# CC1314R10 register map
File version: 1.0
CPU: CM33 1.0, other endian, MPU, FPU, 3 interrupt priority bits
Registers are 32-bit, read-write, reset 0x0 unless marked. A register's access mark holds for its fields unless they carry their own. Offsets are from the block's base; [hi:lo] are bit positions; {n}, {i} and the like mark numbered series.

## WDT — Watchdog Timer
Base 0x40080000
0x00 LOAD reset 0xFFFFFFFF — Configuration
  [31:0] WDTLOAD — [31:0] This register is the 32-bit interval value used by the 32-bit counter. When this register is written, the value is immediately loaded and the counter is restarted to count down from the new value. If this register is loaded with 0x0000.0000, an interrupt is immediately generated.
0x04 VALUE reset 0xFFFFFFFF — Current Count Value
  [31:0] WDTVALUE ro — [31:0] This register contains the current count value of the timer.
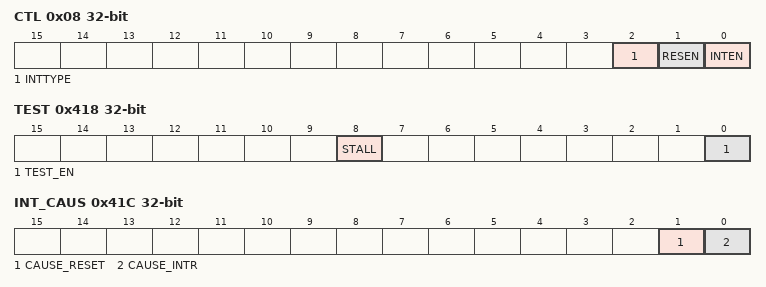
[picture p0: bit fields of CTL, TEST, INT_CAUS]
0x08 CTL — Control
  [2] INTTYPE — [2:2] WDT Interrupt Type 0: WDT interrupt is a standard interrupt. 1: WDT interrupt is a non-maskable interrupt.
    1=NONMASKABLE (Non-maskable interrupt); 0=MASKABLE (Maskable interrupt)
  [1] RESEN — [1:1] WDT Reset Enable. Defines the function of the WDT reset source (see PRCM:WARMRESET.WDT_STAT if enabled) 0: Disabled. 1: Enable the Watchdog reset output.
    1=EN (Reset output Enabled); 0=DIS (Reset output Disabled)
  [0] INTEN — [0:0] WDT Interrupt Enable 0: Interrupt event disabled. 1: Interrupt event enabled. Once set, this bit can only be cleared by a hardware reset.
    1=EN (Interrupt Enabled); 0=DIS (Interrupt Disabled)
0x0C ICR — Interrupt Clear
  [31:0] WDTICR wo — [31:0] This register is the interrupt clear register. A write of any value to this register clears the WDT interrupt and reloads the 32-bit counter from the LOAD register.
0x10 RIS — Raw Interrupt Status
  [0] WDTRIS ro — [0:0] This register is the raw interrupt status register. WDT interrupt events can be monitored via this register if the controller interrupt is masked. Value Description 0: The WDT has not timed out 1: A WDT time-out event has occurred
0x14 MIS — Masked Interrupt Status
  [0] WDTMIS ro — [0:0] This register is the masked interrupt status register. The value of this register is the logical AND of the raw interrupt bit and the WDT interrupt enable bit CTL.INTEN. Value Description 0: The WDT has not timed out or is masked. 1: An unmasked WDT time-out event has occurred.
0x418 TEST — Test Mode
  [8] STALL — [8:8] WDT Stall Enable 0: The WDT timer continues counting if the CPU is stopped with a debugger. 1: If the CPU is stopped with a debugger, the WDT stops counting. Once the CPU is restarted, the WDT resumes counting.
    1=EN (Enable STALL); 0=DIS (Disable STALL)
  [0] TEST_EN — [0:0] The test enable bit 0: Enable external reset 1: Disables the generation of an external reset. Instead bit 1 of the INT_CAUS register is set and an interrupt is generated
    1=EN (Test mode Enabled); 0=DIS (Test mode Disabled)
0x41C INT_CAUS — Interrupt Cause Test Mode
  [1] CAUSE_RESET ro — [1:1] Indicates that the cause of an interrupt was a reset generated but blocked due to TEST.TEST_EN (only possible when TEST.TEST_EN is set).
  [0] CAUSE_INTR ro — [0:0] Replica of RIS.WDTRIS
0xC00 LOCK
  [31:0] WDTLOCK — [31:0] WDT Lock: A write of the value 0x1ACC.E551 unlocks the watchdog registers for write access. A write of any other value reapplies the lock, preventing any register updates (NOTE: TEST.TEST_EN bit is not lockable). A read of this register returns the following values: 0x0000.0000: Unlocked 0x0000.0001: Locked

## SMPH — MCU Semaphore Module This module provides 32 binary semaphores. The state of a binary semaphore is either taken or available. A semaphore does not implement any ownership attribute. Still, a semaphore can be used to handle mutual exclusion scenarios.
Base 0x40084000
{0x0+4i} SMPH{i} reset 0x1 (i=0..31) — MCU SEMAPHORE {i}
  [0] STAT — [0:0] Status when reading: 0: Semaphore is taken 1: Semaphore is available Reading the register causes it to change value to 0. Releasing the semaphore is done by writing 1.
{0x800+4i} PEEK{i} reset 0x1 (i=0..31) — MCU SEMAPHORE {i} ALIAS
  [0] STAT ro — [0:0] Status when reading: 0: Semaphore is taken 1: Semaphore is available Used for semaphore debugging. A read operation will not change register value. Register writing is not possible.
